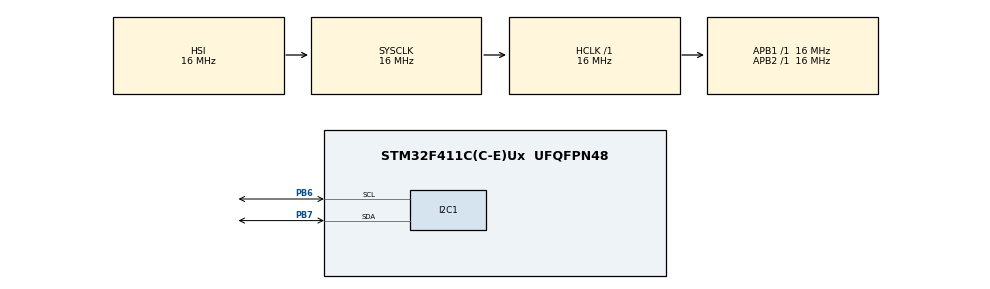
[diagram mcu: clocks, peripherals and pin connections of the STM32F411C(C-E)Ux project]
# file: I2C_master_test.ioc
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Mcu.Family=STM32F4
Mcu.Name=STM32F411C(C-E)Ux
Mcu.Package=UFQFPN48
NVIC.I2C1_ER_IRQn=true\:0\:0\:false\:false\:true\:true\:true
NVIC.I2C1_EV_IRQn=true\:0\:0\:false\:false\:true\:true\:true
NVIC.PriorityGroup=NVIC_PRIORITYGROUP_4
PA13.Mode=Serial_Wire
PA13.Signal=SYS_JTMS-SWDIO
PA14.Mode=Serial_Wire
PA14.Signal=SYS_JTCK-SWCLK
PB6.Mode=I2C
PB6.Signal=I2C1_SCL
PB7.Mode=I2C
PB7.Signal=I2C1_SDA
ProjectManager.HeapSize=0x200
ProjectManager.StackSize=0x400
ProjectManager.TargetToolchain=STM32CubeIDE
RCC.AHBFreq_Value=16000000
RCC.APB1Freq_Value=16000000
RCC.APB2Freq_Value=16000000
RCC.CortexFreq_Value=16000000
RCC.HSE_VALUE=25000000
RCC.HSI_VALUE=16000000
RCC.LSE_VALUE=32768
RCC.SYSCLKFreq_VALUE=16000000
RCC.VCOOutputFreq_Value=192000000
board=custom

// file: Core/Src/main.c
/* USER CODE BEGIN Header */
/**
  ******************************************************************************
  * @file           : main.c
  * @brief          : Main program body
  ******************************************************************************
  * @attention
  *
  * Copyright (c) 2022 STMicroelectronics.
  * All rights reserved.
  *
  * This software is licensed under terms that can be found in the LICENSE file
  * in the root directory of this software component.
  * If no LICENSE file comes with this software, it is provided AS-IS.
  *
  ******************************************************************************
  */
/* USER CODE END Header */
#include "main.h"

/* USER CODE BEGIN Includes */
#include "i2c-crutch.h"
/* USER CODE END Includes */

/* USER CODE BEGIN PTD */
typedef struct main_data {
	uint32_t       pressure; //100 000  Pa

	int16_t       temperature;// 30 1C, 0,1C  t*10->int16_t  -->  t/10

	float       xyz_acceleration[3];//+- 15  a*1000

	float       giroscope_data[3];

	float       magnetometer_data[3];
}main_data_t;

/* USER CODE END PTD */

/* USER CODE BEGIN PD */
#define I2C_ADDRESS    0x77
#define I2C_TIMEOUT    10
/* USER CODE END PD */

I2C_HandleTypeDef hi2c1;

void SystemClock_Config(void);
static void MX_GPIO_Init(void);
static void MX_I2C1_Init(void);

int main(void)
{
  /* USER CODE BEGIN 1 */
	main_data_t main_data;
	main_data.pressure = 100000;
	main_data.temperature = -17;
	main_data.xyz_acceleration[0] = 15;
	main_data.xyz_acceleration[1] = 15;
	main_data.xyz_acceleration[2] = 15;
	main_data.giroscope_data[0] = 10;
	main_data.giroscope_data[1] = 10;
	main_data.giroscope_data[2] = 10;
	main_data.magnetometer_data[0] = 12;
	main_data.magnetometer_data[1] = 12;
	main_data.magnetometer_data[2] = 12;
  /* USER CODE END 1 */

  /* MCU Configuration--------------------------------------------------------*/

  /* Reset of all peripherals, Initializes the Flash interface and the Systick. */
  HAL_Init();

  /* Configure the system clock */
  SystemClock_Config();

  /* USER CODE BEGIN SysInit */
  reset_i2c_1();
  /* USER CODE END SysInit */

  /* Initialize all configured peripherals */
  MX_GPIO_Init();
  MX_I2C1_Init();
  /* USER CODE BEGIN 2 */
  uint16_t data_weight = sizeof(main_data);
  /* USER CODE END 2 */

  /* Infinite loop */
  /* USER CODE BEGIN WHILE */
  while (1)
  {
	  HAL_StatusTypeDef res = HAL_I2C_Master_Transmit(&hi2c1, (I2C_ADDRESS << 1), (uint8_t *)&main_data, data_weight,  I2C_TIMEOUT);
	  if(res == HAL_BUSY)
	  {
		  I2C_ClearBusyFlagErratum(&hi2c1, 100);
	  }
	 HAL_Delay(100);
    /* USER CODE END WHILE */

  }
}

void SystemClock_Config(void)
{
  RCC_OscInitTypeDef RCC_OscInitStruct = {0};
  RCC_ClkInitTypeDef RCC_ClkInitStruct = {0};

  /** Configure the main internal regulator output voltage
  */
  __HAL_RCC_PWR_CLK_ENABLE();
  __HAL_PWR_VOLTAGESCALING_CONFIG(PWR_REGULATOR_VOLTAGE_SCALE1);
  /** Initializes the RCC Oscillators according to the specified parameters
  * in the RCC_OscInitTypeDef structure.
  */
  RCC_OscInitStruct.OscillatorType = RCC_OSCILLATORTYPE_HSI;
  RCC_OscInitStruct.HSIState = RCC_HSI_ON;
  RCC_OscInitStruct.HSICalibrationValue = RCC_HSICALIBRATION_DEFAULT;
  RCC_OscInitStruct.PLL.PLLState = RCC_PLL_NONE;
  if (HAL_RCC_OscConfig(&RCC_OscInitStruct) != HAL_OK)
  {
    Error_Handler();
  }
  /** Initializes the CPU, AHB and APB buses clocks
  */
  RCC_ClkInitStruct.ClockType = RCC_CLOCKTYPE_HCLK|RCC_CLOCKTYPE_SYSCLK
                              |RCC_CLOCKTYPE_PCLK1|RCC_CLOCKTYPE_PCLK2;
  RCC_ClkInitStruct.SYSCLKSource = RCC_SYSCLKSOURCE_HSI;
  RCC_ClkInitStruct.AHBCLKDivider = RCC_SYSCLK_DIV1;
  RCC_ClkInitStruct.APB1CLKDivider = RCC_HCLK_DIV1;
  RCC_ClkInitStruct.APB2CLKDivider = RCC_HCLK_DIV1;

  if (HAL_RCC_ClockConfig(&RCC_ClkInitStruct, FLASH_LATENCY_0) != HAL_OK)
  {
    Error_Handler();
  }
}

static void MX_I2C1_Init(void)
{

  hi2c1.Instance = I2C1;
  hi2c1.Init.ClockSpeed = 100000;
  hi2c1.Init.DutyCycle = I2C_DUTYCYCLE_2;
  hi2c1.Init.OwnAddress1 = 0;
  hi2c1.Init.AddressingMode = I2C_ADDRESSINGMODE_7BIT;
  hi2c1.Init.DualAddressMode = I2C_DUALADDRESS_DISABLE;
  hi2c1.Init.OwnAddress2 = 0;
  hi2c1.Init.GeneralCallMode = I2C_GENERALCALL_DISABLE;
  hi2c1.Init.NoStretchMode = I2C_NOSTRETCH_DISABLE;
  if (HAL_I2C_Init(&hi2c1) != HAL_OK)
  {
    Error_Handler();
  }

}

static void MX_GPIO_Init(void)
{

  /* GPIO Ports Clock Enable */
  __HAL_RCC_GPIOA_CLK_ENABLE();
  __HAL_RCC_GPIOB_CLK_ENABLE();

}

void Error_Handler(void)
{
  __disable_irq();
  while (1)
  {
  }
}
